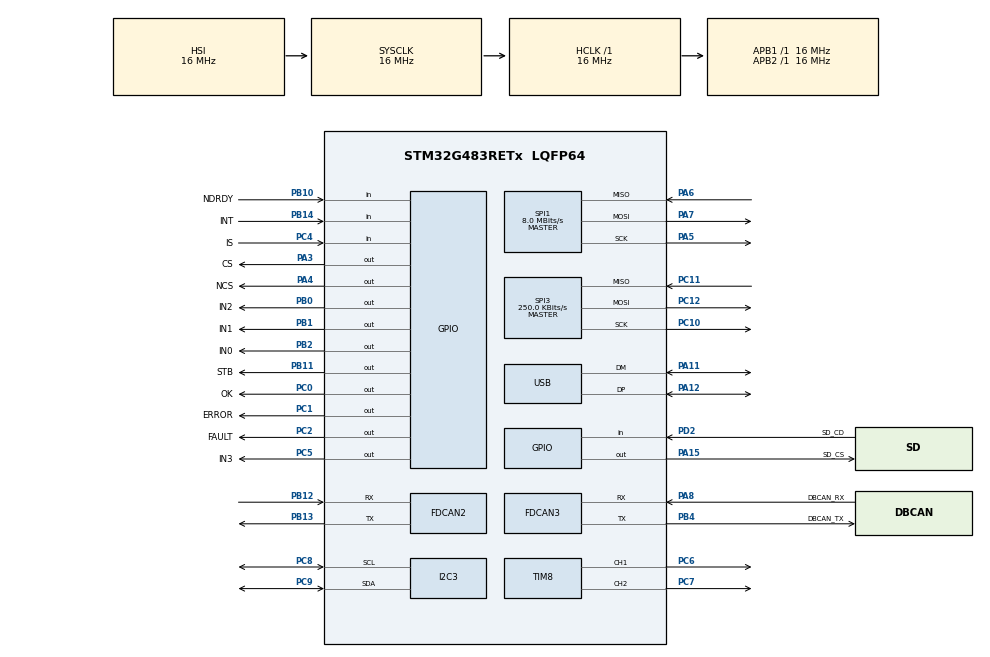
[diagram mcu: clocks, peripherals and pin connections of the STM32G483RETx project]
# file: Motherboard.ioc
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FATFS._CODE_PAGE=437
FATFS._USE_MUTEX=1
FDCAN2.CalculateBaudRateNominal=200000
FDCAN2.CalculateTimeBitNominal=5000
FDCAN2.CalculateTimeQuantumNominal=1000.0
FDCAN3.CalculateBaudRateNominal=200000
FDCAN3.CalculateTimeBitNominal=5000
FDCAN3.CalculateTimeQuantumNominal=1000.0
FREERTOS.Tasks01=defaultTask,24,128,StartDefaultTask,Default,NULL,Dynamic,NULL,NULL;logging,8,1024,StartLoggingTask,Default,NULL,Dynamic,NULL,NULL
FREERTOS.configTOTAL_HEAP_SIZE=32768
I2C3.Timing=0x00503D58
Mcu.Family=STM32G4
Mcu.Name=STM32G483RETx
Mcu.Package=LQFP64
NVIC.PriorityGroup=NVIC_PRIORITYGROUP_4
NVIC.TIM6_DAC_IRQn=true\:15\:0\:false\:false\:true\:false\:false\:true\:true
NVIC.TimeBase=TIM6_DAC_IRQn
NVIC.TimeBaseIP=TIM6
PA11.Mode=Device
PA11.Signal=USB_DM
PA12.Mode=Device
PA12.Signal=USB_DP
PA13.Mode=Serial_Wire
PA13.Signal=SYS_JTMS-SWDIO
PA14.Mode=Serial_Wire
PA14.Signal=SYS_JTCK-SWCLK
PA15.GPIO_Label=SD_CS
PA15.GPIO_Speed=GPIO_SPEED_FREQ_MEDIUM
PA15.PinState=GPIO_PIN_SET
PA15.Signal=GPIO_Output
PA3.GPIO_Label=CS
PA3.Signal=GPIO_Output
PA4.GPIO_Label=NCS
PA4.Signal=GPIO_Output
PA5.Mode=Full_Duplex_Master
PA5.Signal=SPI1_SCK
PA6.Mode=Full_Duplex_Master
PA6.Signal=SPI1_MISO
PA7.Mode=Full_Duplex_Master
PA7.Signal=SPI1_MOSI
PA8.GPIO_Label=DBCAN_RX
PA8.Mode=FDCAN_Activate
PA8.Signal=FDCAN3_RX
PB0.GPIO_Label=IN2
PB0.Signal=GPIO_Output
PB1.GPIO_Label=IN1
PB1.Signal=GPIO_Output
PB10.GPIO_Label=NDRDY
PB10.Signal=GPIO_Input
PB11.GPIO_Label=STB
PB11.Signal=GPIO_Output
PB12.Mode=FDCAN_Activate
PB12.Signal=FDCAN2_RX
PB13.Mode=FDCAN_Activate
PB13.Signal=FDCAN2_TX
PB14.GPIO_Label=INT
PB14.Signal=GPIO_Input
PB2.GPIO_Label=IN0
PB2.Signal=GPIO_Output
PB4.GPIO_Label=DBCAN_TX
PB4.Mode=FDCAN_Activate
PB4.Signal=FDCAN3_TX
PC0.GPIO_Label=OK
PC0.Signal=GPIO_Output
PC1.GPIO_Label=ERROR
PC1.Signal=GPIO_Output
PC10.GPIO_Speed=GPIO_SPEED_FREQ_HIGH
PC10.Mode=Full_Duplex_Master
PC10.Signal=SPI3_SCK
PC11.GPIO_PuPd=GPIO_PULLUP
PC11.GPIO_Speed=GPIO_SPEED_FREQ_HIGH
PC11.Mode=Full_Duplex_Master
PC11.Signal=SPI3_MISO
PC12.GPIO_Speed=GPIO_SPEED_FREQ_HIGH
PC12.Mode=Full_Duplex_Master
PC12.Signal=SPI3_MOSI
PC14-OSC32_IN.Mode=LSE-External-Oscillator
PC14-OSC32_IN.Signal=RCC_OSC32_IN
PC15-OSC32_OUT.Mode=LSE-External-Oscillator
PC15-OSC32_OUT.Signal=RCC_OSC32_OUT
PC2.GPIO_Label=FAULT
PC2.Signal=GPIO_Output
PC4.GPIO_Label=IS
PC4.Signal=GPIO_Input
PC5.GPIO_Label=IN3
PC5.Signal=GPIO_Output
PC6.Signal=S_TIM8_CH1
PC7.Signal=S_TIM8_CH2
PC8.Mode=I2C
PC8.Signal=I2C3_SCL
PC9.Mode=I2C
PC9.Signal=I2C3_SDA
PD2.GPIO_Label=SD_CD
PD2.Signal=GPIO_Input
ProjectManager.HeapSize=0x200
ProjectManager.StackSize=0x400
ProjectManager.TargetToolchain=Makefile
RCC.AHBFreq_Value=16000000
RCC.APB1Freq_Value=16000000
RCC.APB1TimFreq_Value=16000000
RCC.APB2Freq_Value=16000000
RCC.APB2TimFreq_Value=16000000
RCC.CortexFreq_Value=16000000
RCC.EXTERNAL_CLOCK_VALUE=12288000
RCC.HCLKFreq_Value=16000000
RCC.HSE_VALUE=8000000
RCC.HSI48_VALUE=48000000
RCC.HSI_VALUE=16000000
RCC.PLLN=12
RCC.PLLQ=RCC_PLLQ_DIV4
RCC.SYSCLKFreq_VALUE=16000000
RCC.USBFreq_Value=48000000
RCC.VCOOutputFreq_Value=192000000
SH.S_TIM8_CH1.0=TIM8_CH1,PWM Generation1 CH1
SH.S_TIM8_CH2.0=TIM8_CH2,PWM Generation2 CH2
SPI1.CalculateBaudRate=8.0 MBits/s
SPI1.Direction=SPI_DIRECTION_2LINES
SPI1.Mode=SPI_MODE_MASTER
SPI1.VirtualType=VM_MASTER
SPI3.BaudRatePrescaler=SPI_BAUDRATEPRESCALER_64
SPI3.CalculateBaudRate=250.0 KBits/s
SPI3.DataSize=SPI_DATASIZE_8BIT
SPI3.Direction=SPI_DIRECTION_2LINES
SPI3.Mode=SPI_MODE_MASTER
SPI3.NSSPMode=SPI_NSS_PULSE_DISABLE
SPI3.VirtualType=VM_MASTER
TIM8.Channel-PWM\ Generation1\ CH1=TIM_CHANNEL_1
TIM8.Channel-PWM\ Generation2\ CH2=TIM_CHANNEL_2
VP_FATFS_VS_Generic.Mode=User_defined
VP_FREERTOS_VS_CMSIS_V2.Mode=CMSIS_V2
VP_SYS_VS_DBSignals.Mode=DisableDeadBatterySignals
VP_SYS_VS_tim6.Mode=TIM6
board=custom

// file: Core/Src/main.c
/* USER CODE BEGIN Header */
/**
  ******************************************************************************
  * @file           : main.c
  * @brief          : Main program body
  ******************************************************************************
  * @attention
  *
  * Copyright (c) 2026 STMicroelectronics.
  * All rights reserved.
  *
  * This software is licensed under terms that can be found in the LICENSE file
  * in the root directory of this software component.
  * If no LICENSE file comes with this software, it is provided AS-IS.
  *
  ******************************************************************************
  */
/* USER CODE END Header */
#include "main.h"
#include "cmsis_os.h"
#include "app_fatfs.h"

/* USER CODE BEGIN Includes */
#include "user_threads.h"
/* USER CODE END Includes */

FDCAN_HandleTypeDef hfdcan2;
FDCAN_HandleTypeDef hfdcan3;

I2C_HandleTypeDef hi2c3;

SPI_HandleTypeDef hspi1;
SPI_HandleTypeDef hspi3;

TIM_HandleTypeDef htim8;

PCD_HandleTypeDef hpcd_USB_FS;

/* Definitions for defaultTask */
osThreadId_t defaultTaskHandle;
const osThreadAttr_t defaultTask_attributes = {
  .name = "defaultTask",
  .priority = (osPriority_t) osPriorityNormal,
  .stack_size = 128 * 4
};
/* Definitions for logging */
osThreadId_t loggingHandle;
const osThreadAttr_t logging_attributes = {
  .name = "logging",
  .priority = (osPriority_t) osPriorityLow,
  .stack_size = 1024 * 4
};

void SystemClock_Config(void);
static void MX_GPIO_Init(void);
static void MX_FDCAN2_Init(void);
static void MX_FDCAN3_Init(void);
static void MX_I2C3_Init(void);
static void MX_SPI1_Init(void);
static void MX_SPI3_Init(void);
static void MX_TIM8_Init(void);
static void MX_USB_PCD_Init(void);
void StartDefaultTask(void *argument);
void StartLoggingTask(void *argument);

int main(void)
{

  /* MCU Configuration--------------------------------------------------------*/

  /* Reset of all peripherals, Initializes the Flash interface and the Systick. */
  HAL_Init();

  /* Configure the system clock */
  SystemClock_Config();

  /* Initialize all configured peripherals */
  MX_GPIO_Init();
  MX_FDCAN2_Init();
  MX_FDCAN3_Init();
  MX_I2C3_Init();
  MX_SPI1_Init();
  MX_SPI3_Init();
  MX_TIM8_Init();
  MX_USB_PCD_Init();
  if (MX_FATFS_Init() != APP_OK) {
    Error_Handler();
  }

  /* Init scheduler */
  osKernelInitialize();

  /* Create the thread(s) */
  /* creation of defaultTask */
  defaultTaskHandle = osThreadNew(StartDefaultTask, NULL, &defaultTask_attributes);

  /* creation of logging */
  loggingHandle = osThreadNew(StartLoggingTask, NULL, &logging_attributes);

  /* Start scheduler */
  osKernelStart();

  /* We should never get here as control is now taken by the scheduler */

  /* Infinite loop */
  while (1)
  {

  }
}

void SystemClock_Config(void)
{
  RCC_OscInitTypeDef RCC_OscInitStruct = {0};
  RCC_ClkInitTypeDef RCC_ClkInitStruct = {0};

  /** Configure the main internal regulator output voltage
  */
  HAL_PWREx_ControlVoltageScaling(PWR_REGULATOR_VOLTAGE_SCALE1);

  /** Initializes the RCC Oscillators according to the specified parameters
  * in the RCC_OscInitTypeDef structure.
  */
  RCC_OscInitStruct.OscillatorType = RCC_OSCILLATORTYPE_HSI;
  RCC_OscInitStruct.HSIState = RCC_HSI_ON;
  RCC_OscInitStruct.HSICalibrationValue = RCC_HSICALIBRATION_DEFAULT;
  RCC_OscInitStruct.PLL.PLLState = RCC_PLL_ON;
  RCC_OscInitStruct.PLL.PLLSource = RCC_PLLSOURCE_HSI;
  RCC_OscInitStruct.PLL.PLLM = RCC_PLLM_DIV1;
  RCC_OscInitStruct.PLL.PLLN = 12;
  RCC_OscInitStruct.PLL.PLLP = RCC_PLLP_DIV2;
  RCC_OscInitStruct.PLL.PLLQ = RCC_PLLQ_DIV4;
  RCC_OscInitStruct.PLL.PLLR = RCC_PLLR_DIV2;
  if (HAL_RCC_OscConfig(&RCC_OscInitStruct) != HAL_OK)
  {
    Error_Handler();
  }

  /** Initializes the CPU, AHB and APB buses clocks
  */
  RCC_ClkInitStruct.ClockType = RCC_CLOCKTYPE_HCLK|RCC_CLOCKTYPE_SYSCLK
                              |RCC_CLOCKTYPE_PCLK1|RCC_CLOCKTYPE_PCLK2;
  RCC_ClkInitStruct.SYSCLKSource = RCC_SYSCLKSOURCE_HSI;
  RCC_ClkInitStruct.AHBCLKDivider = RCC_SYSCLK_DIV1;
  RCC_ClkInitStruct.APB1CLKDivider = RCC_HCLK_DIV1;
  RCC_ClkInitStruct.APB2CLKDivider = RCC_HCLK_DIV1;

  if (HAL_RCC_ClockConfig(&RCC_ClkInitStruct, FLASH_LATENCY_0) != HAL_OK)
  {
    Error_Handler();
  }
}

static void MX_FDCAN2_Init(void)
{

  hfdcan2.Instance = FDCAN2;
  hfdcan2.Init.ClockDivider = FDCAN_CLOCK_DIV1;
  hfdcan2.Init.FrameFormat = FDCAN_FRAME_CLASSIC;
  hfdcan2.Init.Mode = FDCAN_MODE_NORMAL;
  hfdcan2.Init.AutoRetransmission = DISABLE;
  hfdcan2.Init.TransmitPause = DISABLE;
  hfdcan2.Init.ProtocolException = DISABLE;
  hfdcan2.Init.NominalPrescaler = 16;
  hfdcan2.Init.NominalSyncJumpWidth = 1;
  hfdcan2.Init.NominalTimeSeg1 = 2;
  hfdcan2.Init.NominalTimeSeg2 = 2;
  hfdcan2.Init.DataPrescaler = 1;
  hfdcan2.Init.DataSyncJumpWidth = 1;
  hfdcan2.Init.DataTimeSeg1 = 1;
  hfdcan2.Init.DataTimeSeg2 = 1;
  hfdcan2.Init.StdFiltersNbr = 0;
  hfdcan2.Init.ExtFiltersNbr = 0;
  hfdcan2.Init.TxFifoQueueMode = FDCAN_TX_FIFO_OPERATION;
  if (HAL_FDCAN_Init(&hfdcan2) != HAL_OK)
  {
    Error_Handler();
  }

}

static void MX_FDCAN3_Init(void)
{

  hfdcan3.Instance = FDCAN3;
  hfdcan3.Init.ClockDivider = FDCAN_CLOCK_DIV1;
  hfdcan3.Init.FrameFormat = FDCAN_FRAME_CLASSIC;
  hfdcan3.Init.Mode = FDCAN_MODE_NORMAL;
  hfdcan3.Init.AutoRetransmission = DISABLE;
  hfdcan3.Init.TransmitPause = DISABLE;
  hfdcan3.Init.ProtocolException = DISABLE;
  hfdcan3.Init.NominalPrescaler = 16;
  hfdcan3.Init.NominalSyncJumpWidth = 1;
  hfdcan3.Init.NominalTimeSeg1 = 2;
  hfdcan3.Init.NominalTimeSeg2 = 2;
  hfdcan3.Init.DataPrescaler = 1;
  hfdcan3.Init.DataSyncJumpWidth = 1;
  hfdcan3.Init.DataTimeSeg1 = 1;
  hfdcan3.Init.DataTimeSeg2 = 1;
  hfdcan3.Init.StdFiltersNbr = 0;
  hfdcan3.Init.ExtFiltersNbr = 0;
  hfdcan3.Init.TxFifoQueueMode = FDCAN_TX_FIFO_OPERATION;
  if (HAL_FDCAN_Init(&hfdcan3) != HAL_OK)
  {
    Error_Handler();
  }

}

static void MX_I2C3_Init(void)
{

  hi2c3.Instance = I2C3;
  hi2c3.Init.Timing = 0x00503D58;
  hi2c3.Init.OwnAddress1 = 0;
  hi2c3.Init.AddressingMode = I2C_ADDRESSINGMODE_7BIT;
  hi2c3.Init.DualAddressMode = I2C_DUALADDRESS_DISABLE;
  hi2c3.Init.OwnAddress2 = 0;
  hi2c3.Init.OwnAddress2Masks = I2C_OA2_NOMASK;
  hi2c3.Init.GeneralCallMode = I2C_GENERALCALL_DISABLE;
  hi2c3.Init.NoStretchMode = I2C_NOSTRETCH_DISABLE;
  if (HAL_I2C_Init(&hi2c3) != HAL_OK)
  {
    Error_Handler();
  }

  /** Configure Analogue filter
  */
  if (HAL_I2CEx_ConfigAnalogFilter(&hi2c3, I2C_ANALOGFILTER_ENABLE) != HAL_OK)
  {
    Error_Handler();
  }

  /** Configure Digital filter
  */
  if (HAL_I2CEx_ConfigDigitalFilter(&hi2c3, 0) != HAL_OK)
  {
    Error_Handler();
  }

}

static void MX_SPI1_Init(void)
{

  /* SPI1 parameter configuration*/
  hspi1.Instance = SPI1;
  hspi1.Init.Mode = SPI_MODE_MASTER;
  hspi1.Init.Direction = SPI_DIRECTION_2LINES;
  hspi1.Init.DataSize = SPI_DATASIZE_4BIT;
  hspi1.Init.CLKPolarity = SPI_POLARITY_LOW;
  hspi1.Init.CLKPhase = SPI_PHASE_1EDGE;
  hspi1.Init.NSS = SPI_NSS_SOFT;
  hspi1.Init.BaudRatePrescaler = SPI_BAUDRATEPRESCALER_2;
  hspi1.Init.FirstBit = SPI_FIRSTBIT_MSB;
  hspi1.Init.TIMode = SPI_TIMODE_DISABLE;
  hspi1.Init.CRCCalculation = SPI_CRCCALCULATION_DISABLE;
  hspi1.Init.CRCPolynomial = 7;
  hspi1.Init.CRCLength = SPI_CRC_LENGTH_DATASIZE;
  hspi1.Init.NSSPMode = SPI_NSS_PULSE_ENABLE;
  if (HAL_SPI_Init(&hspi1) != HAL_OK)
  {
    Error_Handler();
  }

}

static void MX_SPI3_Init(void)
{

  /* SPI3 parameter configuration*/
  hspi3.Instance = SPI3;
  hspi3.Init.Mode = SPI_MODE_MASTER;
  hspi3.Init.Direction = SPI_DIRECTION_2LINES;
  hspi3.Init.DataSize = SPI_DATASIZE_8BIT;
  hspi3.Init.CLKPolarity = SPI_POLARITY_LOW;
  hspi3.Init.CLKPhase = SPI_PHASE_1EDGE;
  hspi3.Init.NSS = SPI_NSS_SOFT;
  hspi3.Init.BaudRatePrescaler = SPI_BAUDRATEPRESCALER_64;
  hspi3.Init.FirstBit = SPI_FIRSTBIT_MSB;
  hspi3.Init.TIMode = SPI_TIMODE_DISABLE;
  hspi3.Init.CRCCalculation = SPI_CRCCALCULATION_DISABLE;
  hspi3.Init.CRCPolynomial = 7;
  hspi3.Init.CRCLength = SPI_CRC_LENGTH_DATASIZE;
  hspi3.Init.NSSPMode = SPI_NSS_PULSE_DISABLE;
  if (HAL_SPI_Init(&hspi3) != HAL_OK)
  {
    Error_Handler();
  }

}

static void MX_TIM8_Init(void)
{

  TIM_MasterConfigTypeDef sMasterConfig = {0};
  TIM_OC_InitTypeDef sConfigOC = {0};
  TIM_BreakDeadTimeConfigTypeDef sBreakDeadTimeConfig = {0};

  htim8.Instance = TIM8;
  htim8.Init.Prescaler = 0;
  htim8.Init.CounterMode = TIM_COUNTERMODE_UP;
  htim8.Init.Period = 65535;
  htim8.Init.ClockDivision = TIM_CLOCKDIVISION_DIV1;
  htim8.Init.RepetitionCounter = 0;
  htim8.Init.AutoReloadPreload = TIM_AUTORELOAD_PRELOAD_DISABLE;
  if (HAL_TIM_PWM_Init(&htim8) != HAL_OK)
  {
    Error_Handler();
  }
  sMasterConfig.MasterOutputTrigger = TIM_TRGO_RESET;
  sMasterConfig.MasterOutputTrigger2 = TIM_TRGO2_RESET;
  sMasterConfig.MasterSlaveMode = TIM_MASTERSLAVEMODE_DISABLE;
  if (HAL_TIMEx_MasterConfigSynchronization(&htim8, &sMasterConfig) != HAL_OK)
  {
    Error_Handler();
  }
  sConfigOC.OCMode = TIM_OCMODE_PWM1;
  sConfigOC.Pulse = 0;
  sConfigOC.OCPolarity = TIM_OCPOLARITY_HIGH;
  sConfigOC.OCNPolarity = TIM_OCNPOLARITY_HIGH;
  sConfigOC.OCFastMode = TIM_OCFAST_DISABLE;
  sConfigOC.OCIdleState = TIM_OCIDLESTATE_RESET;
  sConfigOC.OCNIdleState = TIM_OCNIDLESTATE_RESET;
  if (HAL_TIM_PWM_ConfigChannel(&htim8, &sConfigOC, TIM_CHANNEL_1) != HAL_OK)
  {
    Error_Handler();
  }
  if (HAL_TIM_PWM_ConfigChannel(&htim8, &sConfigOC, TIM_CHANNEL_2) != HAL_OK)
  {
    Error_Handler();
  }
  sBreakDeadTimeConfig.OffStateRunMode = TIM_OSSR_DISABLE;
  sBreakDeadTimeConfig.OffStateIDLEMode = TIM_OSSI_DISABLE;
  sBreakDeadTimeConfig.LockLevel = TIM_LOCKLEVEL_OFF;
  sBreakDeadTimeConfig.DeadTime = 0;
  sBreakDeadTimeConfig.BreakState = TIM_BREAK_DISABLE;
  sBreakDeadTimeConfig.BreakPolarity = TIM_BREAKPOLARITY_HIGH;
  sBreakDeadTimeConfig.BreakFilter = 0;
  sBreakDeadTimeConfig.BreakAFMode = TIM_BREAK_AFMODE_INPUT;
  sBreakDeadTimeConfig.Break2State = TIM_BREAK2_DISABLE;
  sBreakDeadTimeConfig.Break2Polarity = TIM_BREAK2POLARITY_HIGH;
  sBreakDeadTimeConfig.Break2Filter = 0;
  sBreakDeadTimeConfig.Break2AFMode = TIM_BREAK_AFMODE_INPUT;
  sBreakDeadTimeConfig.AutomaticOutput = TIM_AUTOMATICOUTPUT_DISABLE;
  if (HAL_TIMEx_ConfigBreakDeadTime(&htim8, &sBreakDeadTimeConfig) != HAL_OK)
  {
    Error_Handler();
  }
  HAL_TIM_MspPostInit(&htim8);

}

static void MX_USB_PCD_Init(void)
{

  hpcd_USB_FS.Instance = USB;
  hpcd_USB_FS.Init.dev_endpoints = 8;
  hpcd_USB_FS.Init.speed = PCD_SPEED_FULL;
  hpcd_USB_FS.Init.phy_itface = PCD_PHY_EMBEDDED;
  hpcd_USB_FS.Init.Sof_enable = DISABLE;
  hpcd_USB_FS.Init.low_power_enable = DISABLE;
  hpcd_USB_FS.Init.lpm_enable = DISABLE;
  hpcd_USB_FS.Init.battery_charging_enable = DISABLE;
  if (HAL_PCD_Init(&hpcd_USB_FS) != HAL_OK)
  {
    Error_Handler();
  }

}

static void MX_GPIO_Init(void)
{
  GPIO_InitTypeDef GPIO_InitStruct = {0};

  /* GPIO Ports Clock Enable */
  __HAL_RCC_GPIOC_CLK_ENABLE();
  __HAL_RCC_GPIOA_CLK_ENABLE();
  __HAL_RCC_GPIOB_CLK_ENABLE();
  __HAL_RCC_GPIOD_CLK_ENABLE();

  /*Configure GPIO pin Output Level */
  HAL_GPIO_WritePin(GPIOC, OK_Pin|ERROR_Pin|FAULT_Pin|IN3_Pin, GPIO_PIN_RESET);

  /*Configure GPIO pin Output Level */
  HAL_GPIO_WritePin(GPIOA, CS_Pin|NCS_Pin, GPIO_PIN_RESET);

  /*Configure GPIO pin Output Level */
  HAL_GPIO_WritePin(GPIOB, IN2_Pin|IN1_Pin|IN0_Pin|STB_Pin, GPIO_PIN_RESET);

  /*Configure GPIO pin Output Level */
  HAL_GPIO_WritePin(SD_CS_GPIO_Port, SD_CS_Pin, GPIO_PIN_SET);

  /*Configure GPIO pins : OK_Pin ERROR_Pin FAULT_Pin IN3_Pin */
  GPIO_InitStruct.Pin = OK_Pin|ERROR_Pin|FAULT_Pin|IN3_Pin;
  GPIO_InitStruct.Mode = GPIO_MODE_OUTPUT_PP;
  GPIO_InitStruct.Pull = GPIO_NOPULL;
  GPIO_InitStruct.Speed = GPIO_SPEED_FREQ_LOW;
  HAL_GPIO_Init(GPIOC, &GPIO_InitStruct);

  /*Configure GPIO pins : CS_Pin NCS_Pin */
  GPIO_InitStruct.Pin = CS_Pin|NCS_Pin;
  GPIO_InitStruct.Mode = GPIO_MODE_OUTPUT_PP;
  GPIO_InitStruct.Pull = GPIO_NOPULL;
  GPIO_InitStruct.Speed = GPIO_SPEED_FREQ_LOW;
  HAL_GPIO_Init(GPIOA, &GPIO_InitStruct);

  /*Configure GPIO pin : IS_Pin */
  GPIO_InitStruct.Pin = IS_Pin;
  GPIO_InitStruct.Mode = GPIO_MODE_INPUT;
  GPIO_InitStruct.Pull = GPIO_NOPULL;
  HAL_GPIO_Init(IS_GPIO_Port, &GPIO_InitStruct);

  /*Configure GPIO pins : IN2_Pin IN1_Pin IN0_Pin STB_Pin */
  GPIO_InitStruct.Pin = IN2_Pin|IN1_Pin|IN0_Pin|STB_Pin;
  GPIO_InitStruct.Mode = GPIO_MODE_OUTPUT_PP;
  GPIO_InitStruct.Pull = GPIO_NOPULL;
  GPIO_InitStruct.Speed = GPIO_SPEED_FREQ_LOW;
  HAL_GPIO_Init(GPIOB, &GPIO_InitStruct);

  /*Configure GPIO pins : NDRDY_Pin INT_Pin */
  GPIO_InitStruct.Pin = NDRDY_Pin|INT_Pin;
  GPIO_InitStruct.Mode = GPIO_MODE_INPUT;
  GPIO_InitStruct.Pull = GPIO_NOPULL;
  HAL_GPIO_Init(GPIOB, &GPIO_InitStruct);

  /*Configure GPIO pin : SD_CS_Pin */
  GPIO_InitStruct.Pin = SD_CS_Pin;
  GPIO_InitStruct.Mode = GPIO_MODE_OUTPUT_PP;
  GPIO_InitStruct.Pull = GPIO_NOPULL;
  GPIO_InitStruct.Speed = GPIO_SPEED_FREQ_MEDIUM;
  HAL_GPIO_Init(SD_CS_GPIO_Port, &GPIO_InitStruct);

  /*Configure GPIO pin : SD_CD_Pin */
  GPIO_InitStruct.Pin = SD_CD_Pin;
  GPIO_InitStruct.Mode = GPIO_MODE_INPUT;
  GPIO_InitStruct.Pull = GPIO_NOPULL;
  HAL_GPIO_Init(SD_CD_GPIO_Port, &GPIO_InitStruct);

}

void StartDefaultTask(void *argument)
{
  /* USER CODE BEGIN 5 */
  /* Infinite loop */
  for(;;)
  {
      userDefaultTask(argument);
  }
  /* USER CODE END 5 */
}

void StartLoggingTask(void *argument)
{
  /* USER CODE BEGIN StartLoggingTask */
    userLoggingTask(argument);
  /* USER CODE END StartLoggingTask */
}

void HAL_TIM_PeriodElapsedCallback(TIM_HandleTypeDef *htim)
{
  if (htim->Instance == TIM6) {
    HAL_IncTick();
  }
}

void Error_Handler(void)
{
  __disable_irq();
  while (1)
  {
  }
}
